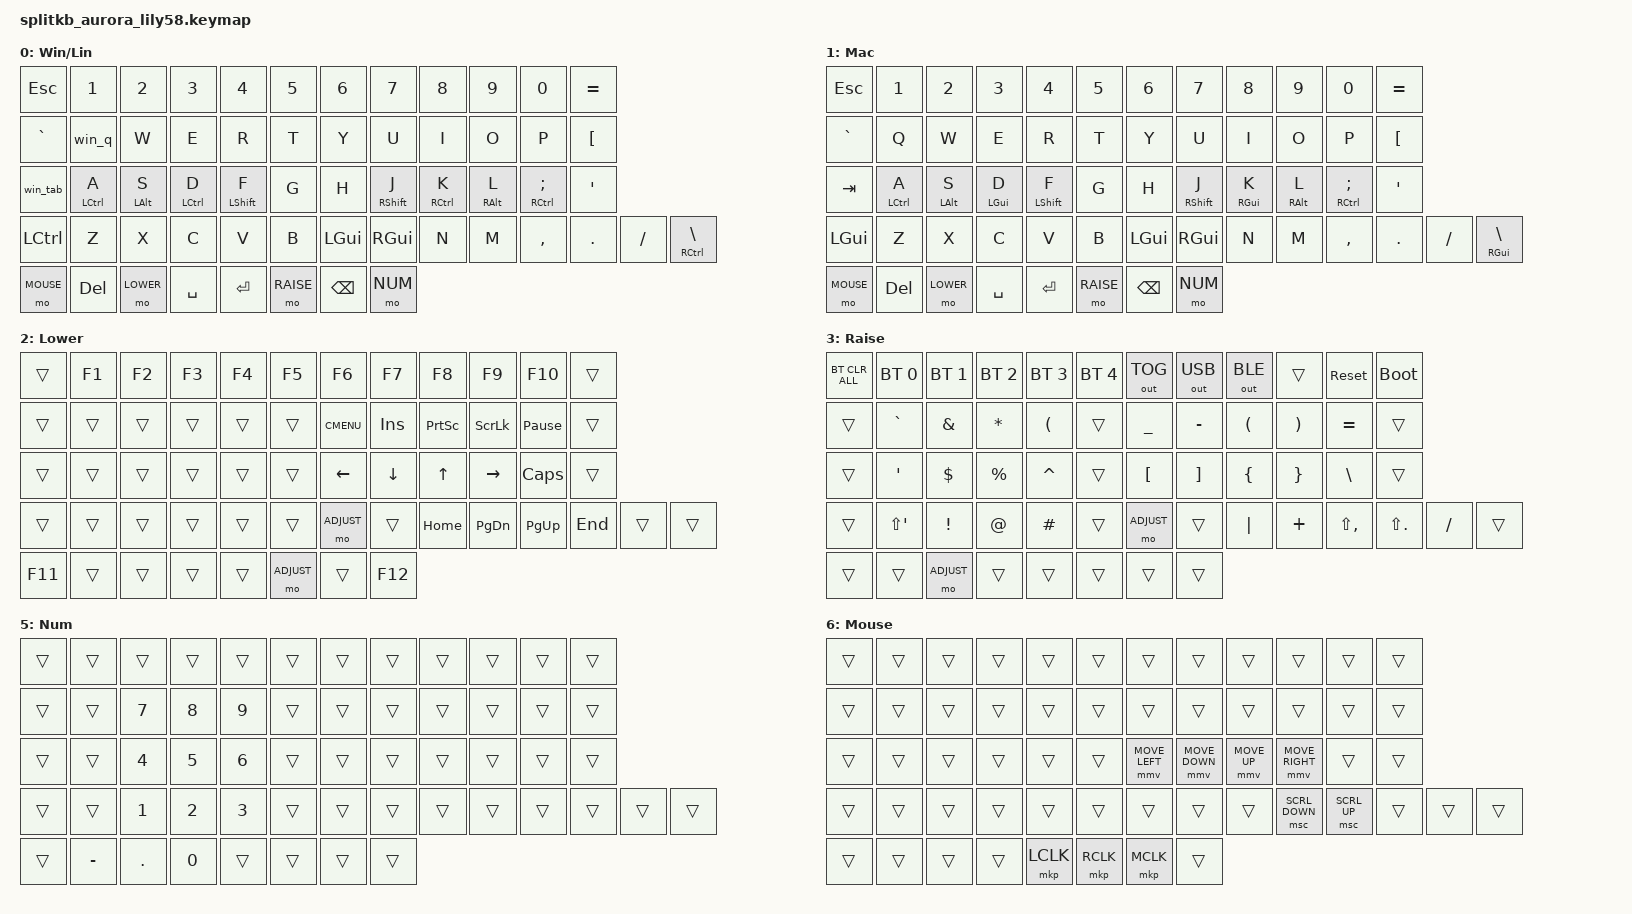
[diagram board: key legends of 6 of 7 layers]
// Aurora Lily58 (58 keys) version of config/lotus58.keymap.
// Generated from lotus58.keymap: the two Lotus centre keys on row 2
// (C_MUTE, the 7th key on each side) are removed, because the Aurora has
// no keys there. Key positions after them shift down by 2.
/*
 * Copyright (c) 2022 The ZMK Contributors
 *
 * SPDX-License-Identifier: MIT
 */

#include <behaviors.dtsi>
#include <dt-bindings/zmk/keys.h>
#include <dt-bindings/zmk/bt.h>
#include <dt-bindings/zmk/outputs.h>
#include <dt-bindings/zmk/pointing.h>
#include <dt-bindings/os_mode.h>
#include <dt-bindings/zmk/rgb.h>
#include <dt-bindings/led_brightness.h>

#define DEFAULT 0
#define MAC     1
#define LOWER   2
#define RAISE   3
#define ADJUST  4
#define NUM     5
#define MOUSE   6

/ {
    behaviors {
        hml: homerow_mod_left {
            compatible = "zmk,behavior-hold-tap";
            #binding-cells = <2>;
            tapping-term-ms = <200>;
            quick-tap-ms = <125>;
            require-prior-idle-ms = <100>;
            flavor = "balanced";
            hold-trigger-on-release;
            hold-trigger-key-positions = <6 7 8 9 10 11 18 19 20 21 22 23 30 31 32 33 34 35 43 44 45 46 47 48 49 50 51 52 53 54 55 56 57>;
            bindings = <&kp>, <&kp>;
        };

        hmr: homerow_mod_right {
            compatible = "zmk,behavior-hold-tap";
            #binding-cells = <2>;
            tapping-term-ms = <200>;
            quick-tap-ms = <125>;
            require-prior-idle-ms = <100>;
            flavor = "balanced";
            hold-trigger-on-release;
            hold-trigger-key-positions = <0 1 2 3 4 5 12 13 14 15 16 17 24 25 26 27 28 29 36 37 38 39 40 41 42 50 51 52 53 54 55 56 57>;
            bindings = <&kp>, <&kp>;
        };
    };

    behaviors {
        // Mac/Win mode saved per connection (each BT profile, and USB).
        // The Mac layer follows the active profile automatically, also after a reboot.
        // See src/os_mode.c.
        os_mode: os_mode {
            compatible = "zmk,behavior-os-mode";
            #binding-cells = <1>;
            mac-layer = <MAC>;
        };

        // nice!view animation mode on/off, saved in flash. See src/display_anim.c
        // and nice_view/widgets/anim.c.
        disp_anim: display_anim {
            compatible = "zmk,behavior-display-anim";
            #binding-cells = <0>;
        };

        // LED brightness in 2% steps, 1% below 2% (Adjust + E/R).
        // See src/behavior_led_brightness.c.
        led_brt: led_brightness {
            compatible = "zmk,behavior-led-brightness";
            #binding-cells = <2>;
        };

        // Alt+Tab app switcher (zmk-tri-state module, see config/west.yml).
        // First press: Alt down + Tab. Further presses: Tab (Alt stays down).
        // Pressing or releasing any other key (e.g. letting go of K) releases Alt.
        // F and J (Shift) are ignored so Shift+Tab steps backwards.
        alt_tab: alt_tab {
            compatible = "zmk,behavior-tri-state";
            #binding-cells = <0>;
            bindings = <&kt LALT>, <&kp TAB>, <&kt LALT>;
            ignored-key-positions = <28 31>;
        };

        // Win mode Tab (TAB* in the diagram below): with Ctrl held (D/K, the Mac Cmd positions) it becomes the
        // Alt+Tab switcher, matching Cmd+Tab on the Mac. Ctrl is hidden from the host
        // while Tab is sent. Plain Tab is unchanged.
        win_tab: win_tab {
            compatible = "zmk,behavior-mod-morph";
            #binding-cells = <0>;
            bindings = <&kp TAB>, <&alt_tab>;
            mods = <(MOD_LCTL|MOD_RCTL)>;
        };

        // Win mode Q (Q* in the diagram below): Ctrl+Q sends Alt+F4 (close the app),
        // matching Cmd+Q on the Mac. Plain Q is unchanged.
        win_q: win_q {
            compatible = "zmk,behavior-mod-morph";
            #binding-cells = <0>;
            bindings = <&kp Q>, <&kp LA(F4)>;
            mods = <(MOD_LCTL|MOD_RCTL)>;
        };
    };

    keymap {
        compatible = "zmk,keymap";

        default_layer {
            display-name = "Win/Lin";
// ┌─────────┬─────┬─────┬─────┬──────────┬─────┐                            ┌─────┬──────────┬──────────┬──────────┬──────────┬────────┐
// │   ESC   │  1  │  2  │  3  │    4     │  5  │                            │  6  │    7     │    8     │    9     │    0     │   =    │
// ├─────────┼─────┼─────┼─────┼──────────┼─────┤                            ├─────┼──────────┼──────────┼──────────┼──────────┼────────┤
// │    `    │ Q*  │  W  │  E  │    R     │  T  │                            │  Y  │    U     │    I     │    O     │    P     │   [    │
// ├─────────┼─────┼─────┼─────┼──────────┼─────┼──────────┐  ┌─────────────┼─────┼──────────┼──────────┼──────────┼──────────┼────────┤
// │  TAB*   │CTL/A│ALT/S│CTL/D│  SHF/F  │  G  │   MUTE   │  │    MUTE     │  H  │  SHF/J  │  CTL/K  │  ALT/L  │  CTL/;  │   '    │
// ├─────────┼─────┼─────┼─────┼──────────┼─────┼──────────┤  ├─────────────┼─────┼──────────┼──────────┼──────────┼──────────┼────────┤
// │  LCTRL  │  Z  │  X  │  C  │    V     │  B  │   LGUI   │  │    RGUI     │  N  │    M     │    ,     │    .     │    /     │ RCTL/\ │
// └─────────┴─────┴─────┴─────┴──────────┴─────┴──────────┘  └─────────────┴─────┴──────────┴──────────┴──────────┴──────────┴────────┘
//                     ┌──────┬──────┬───────┬────────┐      ┌──────┬───────┬──────┬──────┐
//                     │MOUSE │ DEL  │ LOWER │  SPC   │      │ ENT  │ RAISE │ BSPC │ NUM  │
//                     └──────┴──────┴───────┴────────┘      └──────┴───────┴──────┴──────┘
            bindings = <
    &kp ESC       &kp N1        &kp N2        &kp N3        &kp N4        &kp N5        &kp N6        &kp N7        &kp N8        &kp N9        &kp N0        &kp EQUAL
    &kp GRAVE     &win_q        &kp W         &kp E         &kp R         &kp T         &kp Y         &kp U         &kp I         &kp O         &kp P         &kp LBKT
    &win_tab      &hml LCTRL A  &hml LALT S   &hml LCTRL D  &hml LSHFT F  &kp G         &kp H         &hmr RSHFT J  &hmr RCTRL K  &hmr RALT L   &hmr RCTRL SEMI  &kp SQT
    &kp LCTRL     &kp Z         &kp X         &kp C         &kp V         &kp B         &kp LGUI      &kp RGUI      &kp N         &kp M         &kp COMMA     &kp DOT       &kp FSLH      &mt RCTRL BSLH
    &mo MOUSE     &kp DEL       &mo LOWER     &kp SPACE     &kp RET       &mo RAISE     &kp BSPC      &mo NUM
            >;
            sensor-bindings = <&inc_dec_kp C_VOL_DN C_VOL_UP &inc_dec_kp PG_UP PG_DN>;
        };

        mac_layer {
            display-name = "Mac";
// CAGS order: A=Ctl, S=Alt, D=GUI, F=Shft (left); J=Shft, K=GUI, L=Alt, ;=Ctl (right).
// Bottom-left corner: LGUI. Thumbs: LCTRL (was LGUI), RCTRL (was RGUI). Bottom-right mod-tap: RGUI/\.
// ┌─────────┬─────┬─────┬─────┬──────────┬─────┐                            ┌─────┬──────────┬──────────┬──────────┬──────────┬────────┐
// │   ESC   │  1  │  2  │  3  │    4     │  5  │                            │  6  │    7     │    8     │    9     │    0     │   =    │
// ├─────────┼─────┼─────┼─────┼──────────┼─────┤                            ├─────┼──────────┼──────────┼──────────┼──────────┼────────┤
// │    `    │  Q  │  W  │  E  │    R     │  T  │                            │  Y  │    U     │    I     │    O     │    P     │   [    │
// ├─────────┼─────┼─────┼─────┼──────────┼─────┼──────────┐  ┌─────────────┼─────┼──────────┼──────────┼──────────┼──────────┼────────┤
// │   TAB   │CTL/A│ALT/S│GUI/D│  SHF/F  │  G  │   MUTE   │  │    MUTE     │  H  │  SHF/J  │  GUI/K  │  ALT/L  │  CTL/;  │   '    │
// ├─────────┼─────┼─────┼─────┼──────────┼─────┼──────────┤  ├─────────────┼─────┼──────────┼──────────┼──────────┼──────────┼────────┤
// │  LGUI   │  Z  │  X  │  C  │    V     │  B  │   LGUI   │  │    RGUI     │  N  │    M     │    ,     │    .     │    /     │ RGUI/\ │
// └─────────┴─────┴─────┴─────┴──────────┴─────┴──────────┘  └─────────────┴─────┴──────────┴──────────┴──────────┴──────────┴────────┘
//                     ┌───────┬──────┬───────┬────────┐      ┌──────┬───────┬──────┬───────┐
//                     │ MOUSE │ DEL  │ LOWER │  SPC   │      │ ENT  │ RAISE │ BSPC │  NUM  │
//                     └───────┴──────┴───────┴────────┘      └──────┴───────┴──────┴───────┘
            bindings = <
    &kp ESC       &kp N1        &kp N2        &kp N3        &kp N4        &kp N5        &kp N6        &kp N7        &kp N8        &kp N9        &kp N0        &kp EQUAL
    &kp GRAVE     &kp Q         &kp W         &kp E         &kp R         &kp T         &kp Y         &kp U         &kp I         &kp O         &kp P         &kp LBKT
    &kp TAB       &hml LCTRL A  &hml LALT S   &hml LGUI D   &hml LSHFT F  &kp G         &kp H         &hmr RSHFT J  &hmr RGUI K   &hmr RALT L   &hmr RCTRL SEMI  &kp SQT
    &kp LGUI      &kp Z         &kp X         &kp C         &kp V         &kp B         &kp LGUI      &kp RGUI      &kp N         &kp M         &kp COMMA     &kp DOT       &kp FSLH      &mt RGUI BSLH
    &mo MOUSE     &kp DEL       &mo LOWER     &kp SPACE     &kp RET       &mo RAISE     &kp BSPC      &mo NUM
            >;
            sensor-bindings = <&inc_dec_kp C_VOL_DN C_VOL_UP &inc_dec_kp PG_UP PG_DN>;
        };

        lower_layer {
            display-name = "Lower";
// Left side transparent (falls through to default alpha keys).
// Right side: HJKL arrows on home row, Home/PgDn/PgUp/End on Z row.
// ┌─────────┬─────┬─────┬─────┬─────┬─────┐                            ┌───────┬──────┬───────┬──────┬───────┬────────┐
// │         │  F1 │  F2 │  F3 │  F4 │  F5 │                            │  F6   │  F7  │  F8   │  F9  │  F10  │        │
// ├─────────┼─────┼─────┼─────┼─────┼─────┤                            ├───────┼──────┼───────┼──────┼───────┼────────┤
// │         │     │     │     │     │     │                            │ MENU  │ INS  │ PSCR  │ SLCK │ PAUSE │        │
// ├─────────┼─────┼─────┼─────┼─────┼─────┼──────────┐  ┌─────────────┼───────┼──────┼───────┼──────┼───────┼────────┤
// │         │     │     │     │     │     │          │  │             │  ←    │  ↓   │   ↑   │  →   │ CAPS  │        │
// ├─────────┼─────┼─────┼─────┼─────┼─────┼──────────┤  ├─────────────┼───────┼──────┼───────┼──────┼───────┼────────┤
// │         │     │     │     │     │     │  ADJUST  │  │             │ HOME  │ PG↓  │  PG↑  │ END  │       │        │
// └─────────┴─────┴─────┴─────┴─────┴─────┴──────────┘  └─────────────┴───────┴──────┴───────┴──────┴───────┴────────┘
//                     ┌──────┬──────┬───────┬────────┐      ┌──────┬────────┬──────┬──────┐
//                     │  F11 │      │▓▓▓▓▓▓▓│        │      │      │ ADJUST │      │  F12 │
//                     └──────┴──────┴───────┴────────┘      └──────┴────────┴──────┴──────┘
            bindings = <
    &trans        &kp F1        &kp F2        &kp F3        &kp F4        &kp F5        &kp F6        &kp F7        &kp F8        &kp F9        &kp F10       &trans
    &trans        &trans        &trans        &trans        &trans        &trans        &kp K_CMENU   &kp INS       &kp PSCRN     &kp SLCK      &kp PAUSE_BREAK  &trans
    &trans        &trans        &trans        &trans        &trans        &trans        &kp LEFT      &kp DOWN      &kp UP        &kp RIGHT     &kp CLCK      &trans
    &trans        &trans        &trans        &trans        &trans        &trans        &mo ADJUST    &trans        &kp HOME      &kp PG_DN     &kp PG_UP     &kp END       &trans        &trans
    &kp F11       &trans        &trans        &trans        &trans        &mo ADJUST    &trans        &kp F12
            >;
            sensor-bindings = <&inc_dec_kp C_VOL_DN C_VOL_UP &inc_dec_kp C_NEXT C_PREV>;
        };

        raise_layer {
            display-name = "Raise";
// Symbols verbatim from hillside Layer 2. Left = ` & * ( / ' $ % ^ / " ! @ #
//                                         Right = _ - ( ) = / [ ] { } \ / | + < > /
// BT and system on number row.
// ┌───────────┬───────┬───────┬───────┬───────┬───────┐                         ┌─────────┬────────┬────────┬──────┬────────┬──────────┐
// │  BT CLR   │  BT1  │  BT2  │  BT3  │  BT4  │  BT5  │                         │ OUT TOG │OUT USB │OUT BLE │      │ RESET  │  FLASH   │
// ├───────────┼───────┼───────┼───────┼───────┼───────┤                         ├─────────┼────────┼────────┼──────┼────────┼──────────┤
// │           │   `   │   &   │   *   │   (   │       │                         │    _    │   -    │   (    │  )   │   =    │          │
// ├───────────┼───────┼───────┼───────┼───────┼───────┼──────────┐ ┌────────────┼─────────┼────────┼────────┼──────┼────────┼──────────┤
// │           │   '   │   $   │   %   │   ^   │       │          │ │            │    [    │   ]    │   {    │  }   │   \    │          │
// ├───────────┼───────┼───────┼───────┼───────┼───────┼──────────┤ ├────────────┼─────────┼────────┼────────┼──────┼────────┼──────────┤
// │           │   "   │   !   │   @   │   #   │       │  ADJUST  │ │            │    |    │   +    │   <    │  >   │   /    │          │
// └───────────┴───────┴───────┴───────┴───────┴───────┴──────────┘ └────────────┴─────────┴────────┴────────┴──────┴────────┴──────────┘
//                         ┌──────┬──────┬────────┬──────┐      ┌──────┬──────┬──────┬──────┐
//                         │      │      │ ADJUST │      │      │      │▓▓▓▓▓▓│      │      │
//                         └──────┴──────┴────────┴──────┘      └──────┴──────┴──────┴──────┘
            bindings = <
    &bt BT_CLR_ALL  &bt BT_SEL 0  &bt BT_SEL 1  &bt BT_SEL 2  &bt BT_SEL 3  &bt BT_SEL 4  &out OUT_TOG  &out OUT_USB  &out OUT_BLE  &trans        &sys_reset    &bootloader
    &trans        &kp GRAVE     &kp AMPS      &kp STAR      &kp LPAR      &trans        &kp UNDER     &kp MINUS     &kp LPAR      &kp RPAR      &kp EQUAL     &trans
    &trans        &kp SQT       &kp DLLR      &kp PRCNT     &kp CARET     &trans        &kp LBKT      &kp RBKT      &kp LBRC      &kp RBRC      &kp BSLH      &trans
    &trans        &kp LS(SQT)   &kp EXCL      &kp AT        &kp HASH      &trans        &mo ADJUST    &trans        &kp PIPE      &kp PLUS      &kp LS(COMMA)  &kp LS(DOT)   &kp FSLH      &trans
    &trans        &trans        &mo ADJUST    &trans        &trans        &trans        &trans        &trans
            >;
            sensor-bindings = <&inc_dec_kp C_VOL_DN C_VOL_UP &inc_dec_kp PG_UP PG_DN>;
        };

        adjust_layer {
            display-name = "Adjust";
// Top row: BT profiles 1-5 (ZMK's BT_SEL 0-4). Each profile remembers its own Mac/Win mode.
// OS on A and ; (the GUI home-row keys): flip the current profile between Mac and Win mods.
// The choice is written to flash 60 s after the press (ZMK's settings save delay), so
// wait a minute before powering off.
// Mouse keys live on the Mouse layer (left outer thumb).
// ┌─────────┬──────────┬──────────┬──────────┬──────────┬───────┐                         ┌───────┬───────┬───────┬───────┬───────┬───────┐
// │         │   BT1    │   BT2    │   BT3    │   BT4    │  BT5  │                         │       │       │       │       │       │       │
// ├─────────┼──────────┼──────────┼──────────┼──────────┼───────┤                         ├───────┼───────┼───────┼───────┼───────┼───────┤
// │         │          │          │          │          │       │                         │       │       │       │       │       │       │
// ├─────────┼──────────┼──────────┼──────────┼──────────┼───────┼──────────┐ ┌────────────┼───────┼───────┼───────┼───────┼───────┼───────┤
// │         │    OS    │          │   Anim   │          │       │          │ │            │       │       │ Anim  │       │  OS   │       │
// ├─────────┼──────────┼──────────┼──────────┼──────────┼───────┼──────────┤ ├────────────┼───────┼───────┼───────┼───────┼───────┼───────┤
// │         │          │          │          │          │       │          │ │            │       │       │       │       │       │       │
// └─────────┴──────────┴──────────┴──────────┴──────────┴───────┴──────────┘ └────────────┴───────┴───────┴───────┴───────┴───────┴───────┘
//                           ┌────────┬─────────┬───────┬───────┐      ┌───────┬───────┬───────┬───────┐
//                           │        │         │       │       │      │       │       │       │       │
//                           └────────┴─────────┴───────┴───────┘      └───────┴───────┴───────┴───────┘
// LED keys (Adjust): Q on/off (cuts power, screen too), W dark (power stays on),
// E/R brightness -/+ (2% steps, 1% below 2%), T white 10%, Z/X hue -/+, C/V saturation -/+, B next effect.
            bindings = <
    &trans          &bt BT_SEL 0    &bt BT_SEL 1    &bt BT_SEL 2    &bt BT_SEL 3    &bt BT_SEL 4    &trans          &trans          &trans          &trans          &trans          &trans
    &trans          &rgb_ug RGB_TOG  &rgb_ug RGB_COLOR_HSB(0,0,0)  &led_brt LED_BRD  &led_brt LED_BRI  &rgb_ug RGB_COLOR_HSB(0,0,10)  &trans          &trans          &trans          &trans          &trans          &trans
    &trans          &os_mode OS_TOG  &trans          &disp_anim      &trans          &trans          &trans          &trans          &disp_anim      &trans          &os_mode OS_TOG  &trans
    &trans          &rgb_ug RGB_HUD  &rgb_ug RGB_HUI  &rgb_ug RGB_SAD  &rgb_ug RGB_SAI  &rgb_ug RGB_EFF  &trans          &trans          &trans          &trans          &trans          &trans          &trans          &trans
    &trans          &trans          &trans          &trans          &trans          &trans          &trans          &trans
            >;
            sensor-bindings = <&inc_dec_kp C_VOL_DN C_VOL_UP &inc_dec_kp PG_UP PG_DN>;
        };

        num_layer {
            display-name = "Num";
// Hold the right outer thumb. Left hand is a numpad (Miryoku style: layer on one
// hand, keys on the other). Shift + digit still gives the usual symbol.
// Number row stays as-is for now.
// ┌─────────┬─────┬─────┬─────┬─────┬─────┐                            ┌─────┬─────┬─────┬─────┬─────┬─────┐
// │         │     │     │     │     │     │                            │     │     │     │     │     │     │
// ├─────────┼─────┼─────┼─────┼─────┼─────┤                            ├─────┼─────┼─────┼─────┼─────┼─────┤
// │         │     │  7  │  8  │  9  │     │                            │     │     │     │     │     │     │
// ├─────────┼─────┼─────┼─────┼─────┼─────┼──────────┐  ┌─────────────┼─────┼─────┼─────┼─────┼─────┼─────┤
// │         │     │  4  │  5  │  6  │     │          │  │             │     │     │     │     │     │     │
// ├─────────┼─────┼─────┼─────┼─────┼─────┼──────────┤  ├─────────────┼─────┼─────┼─────┼─────┼─────┼─────┤
// │         │     │  1  │  2  │  3  │     │          │  │             │     │     │     │     │     │     │
// └─────────┴─────┴─────┴─────┴─────┴─────┴──────────┘  └─────────────┴─────┴─────┴─────┴─────┴─────┴─────┘
//                     ┌──────┬──────┬───────┬────────┐      ┌──────┬───────┬──────┬──────┐
//                     │      │  -   │   .   │   0    │      │      │       │      │▓▓▓▓▓▓│
//                     └──────┴──────┴───────┴────────┘      └──────┴───────┴──────┴──────┘
            bindings = <
    &trans        &trans        &trans        &trans        &trans        &trans        &trans        &trans        &trans        &trans        &trans        &trans
    &trans        &trans        &kp N7        &kp N8        &kp N9        &trans        &trans        &trans        &trans        &trans        &trans        &trans
    &trans        &trans        &kp N4        &kp N5        &kp N6        &trans        &trans        &trans        &trans        &trans        &trans        &trans
    &trans        &trans        &kp N1        &kp N2        &kp N3        &trans        &trans        &trans        &trans        &trans        &trans        &trans        &trans        &trans
    &trans        &kp MINUS     &kp DOT       &kp N0        &trans        &trans        &trans        &trans
            >;
            sensor-bindings = <&inc_dec_kp C_VOL_DN C_VOL_UP &inc_dec_kp PG_UP PG_DN>;
        };

        mouse_layer {
            display-name = "Mouse";
// Hold the left outer thumb. Right hand moves the mouse (Miryoku style): movement on
// H J K L like the Lower arrows, scroll on M , like Lower PgDn/PgUp, buttons on the
// right thumbs.
// ┌─────────┬─────┬─────┬─────┬─────┬─────┐                            ┌───────┬───────┬───────┬───────┬─────┬─────┐
// │         │     │     │     │     │     │                            │       │       │       │       │     │     │
// ├─────────┼─────┼─────┼─────┼─────┼─────┤                            ├───────┼───────┼───────┼───────┼─────┼─────┤
// │         │     │     │     │     │     │                            │       │       │       │       │     │     │
// ├─────────┼─────┼─────┼─────┼─────┼─────┼──────────┐  ┌─────────────┼───────┼───────┼───────┼───────┼─────┼─────┤
// │         │     │     │     │     │     │          │  │             │MOUSE← │MOUSE↓ │MOUSE↑ │MOUSE→ │     │     │
// ├─────────┼─────┼─────┼─────┼─────┼─────┼──────────┤  ├─────────────┼───────┼───────┼───────┼───────┼─────┼─────┤
// │         │     │     │     │     │     │          │  │             │       │ SCR↓  │ SCR↑  │       │     │     │
// └─────────┴─────┴─────┴─────┴─────┴─────┴──────────┘  └─────────────┴───────┴───────┴───────┴───────┴─────┴─────┘
//                     ┌──────┬──────┬───────┬────────┐      ┌────────┬────────┬────────┬──────┐
//                     │▓▓▓▓▓▓│      │       │        │      │L CLICK │R CLICK │M CLICK │      │
//                     └──────┴──────┴───────┴────────┘      └────────┴────────┴────────┴──────┘
            bindings = <
    &trans        &trans        &trans        &trans        &trans        &trans        &trans        &trans        &trans        &trans        &trans        &trans
    &trans        &trans        &trans        &trans        &trans        &trans        &trans        &trans        &trans        &trans        &trans        &trans
    &trans        &trans        &trans        &trans        &trans        &trans        &mmv MOVE_LEFT  &mmv MOVE_DOWN  &mmv MOVE_UP  &mmv MOVE_RIGHT  &trans        &trans
    &trans        &trans        &trans        &trans        &trans        &trans        &trans        &trans        &trans        &msc SCRL_DOWN  &msc SCRL_UP  &trans        &trans        &trans
    &trans        &trans        &trans        &trans        &mkp LCLK     &mkp RCLK     &mkp MCLK     &trans
            >;
            sensor-bindings = <&inc_dec_kp C_VOL_DN C_VOL_UP &inc_dec_kp PG_UP PG_DN>;
        };
    };
};

/*
 * Aurora Lily58: nice!view chip-select on the DATA hole (nice!nano P0.08 =
 * pro_micro 0). The stock nice_view_adapter uses pro_micro 1 (P0.06).
 *
 * This lives in the keymap file, not a separate overlay, because ZMK parses
 * the config overlays before nice_view_adapter, which sets cs-gpios on spi0.
 * The keymap is parsed after it. Labelled &spi0 rather than &nice_view_spi
 * because this file is also parsed for the right half, which has no adapter
 * and no nice_view_spi label. spi0 exists on both halves.
 */
&spi0 {
    cs-gpios = <&pro_micro 0 GPIO_ACTIVE_HIGH>;
};

/*
 * Aurora Lily58 per-key LEDs: 29 per half.
 *
 * ZMK's own splitkb_aurora_lily58 shield already defines the LED chain
 * (SPI3 MOSI on P0.06) in boards/nice_nano_v2.overlay, with a placeholder
 * chain-length of 5. That file is parsed after the config overlays, so the
 * length has to be set here, in the keymap, which is parsed last. Applies to
 * both halves.
 */
&led_strip {
    chain-length = <29>;
};

/*
 * Per-key reactive LEDs (src/reactive_led.c): the LED under a pressed key
 * flashes to twice its brightness and fades back over fade-ms. ZMK's
 * underglow draws into this node, which passes frames on to the real strip.
 *
 * key-leds: LED number for each key position, from the Aurora Lily58 schematic.
 *   Left chain:  SW1-6 (top row, outer->inner), SW7-12, SW13-18,
 *                SW20-25 (bottom row, outer->inner), SW19 (inner key), SW26-29 (thumbs, outer->inner)
 *   Right chain: SW6-1 (top row, inner->outer), SW12-7, SW18-13,
 *                SW19 (inner key), SW25-21, SW20 (outer), SW29-26 (thumbs, inner->outer)
 * Read in keymap order, both halves come out as the same numbers.
 */
/ {
    reactive_strip: reactive_strip {
        compatible = "zmk,reactive-led-strip";
        led-strip = <&led_strip>;
        chain-length = <29>;
        fade-ms = <400>;
        key-leds = <
             0  1  2  3  4  5                       0  1  2  3  4  5
             6  7  8  9 10 11                       6  7  8  9 10 11
            12 13 14 15 16 17                      12 13 14 15 16 17
            18 19 20 21 22 23 24                18 19 20 21 22 23 24
                     25 26 27 28          25 26 27 28
        >;
    };

    chosen {
        zmk,underglow = &reactive_strip;
    };
};
